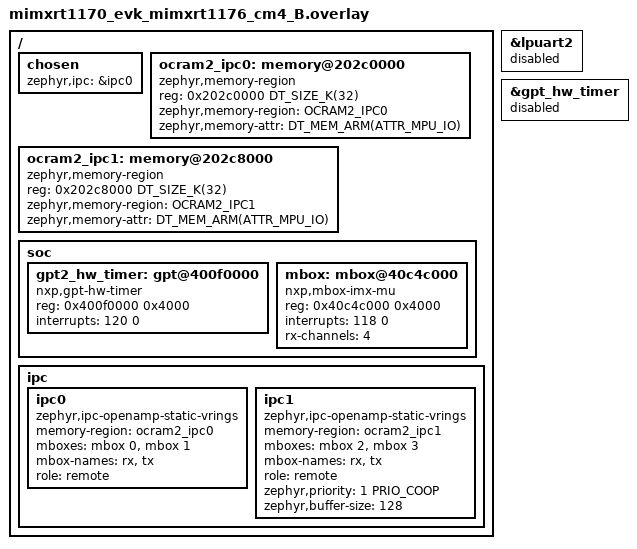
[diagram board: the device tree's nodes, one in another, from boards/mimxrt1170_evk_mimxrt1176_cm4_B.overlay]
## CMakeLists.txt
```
cmake_minimum_required(VERSION 3.20.0)
find_package(Zephyr REQUIRED HINTS $ENV{ZEPHYR_BASE})
project(cm4_rpmsg)

target_sources(app PRIVATE
    src/main.c
    src/ipc_handler.c
    src/cmd_dispatch.c
    src/debug.c
)
```

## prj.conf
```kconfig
CONFIG_IPC_SERVICE=y
CONFIG_MBOX=y
CONFIG_OPENAMP=y
CONFIG_OPENAMP_MASTER=n
CONFIG_HEAP_MEM_POOL_SIZE=4096
CONFIG_LOG=y
CONFIG_IPC_SERVICE_LOG_LEVEL_INF=y
CONFIG_MAIN_STACK_SIZE=2048
CONFIG_UART_CONSOLE=n
CONFIG_STDOUT_CONSOLE=n
CONFIG_BUILD_OUTPUT_INFO_HEADER=y
CONFIG_BUILD_OUTPUT_HEX=y
```

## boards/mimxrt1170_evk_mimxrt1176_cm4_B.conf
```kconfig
CONFIG_MBOX_NXP_IMX_MU=y
CONFIG_BUILD_OUTPUT_HEX=y
CONFIG_BUILD_OUTPUT_INFO_HEADER=y
CONFIG_SECOND_CORE_MCUX=y
```

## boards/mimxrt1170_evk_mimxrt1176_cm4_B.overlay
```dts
#include <zephyr/dt-bindings/ipc_service/static_vrings.h>
#include <zephyr/dt-bindings/memory-attr/memory-attr-arm.h>

/ {
    chosen {
        /delete-property/ zephyr,console;
        /delete-property/ zephyr,shell-uart;
        /delete-property/ zephyr,ipc;
        /delete-property/ zephyr,ipc_shm;
        zephyr,ipc = &ipc0;
    };

    ocram2_ipc0: memory@202c0000 {
        compatible = "zephyr,memory-region", "mmio-sram";
        reg = <0x202c0000 DT_SIZE_K(32)>;
        zephyr,memory-region = "OCRAM2_IPC0";
        zephyr,memory-attr = <DT_MEM_ARM(ATTR_MPU_IO)>;
    };

    ocram2_ipc1: memory@202c8000 {
        compatible = "zephyr,memory-region", "mmio-sram";
        reg = <0x202c8000 DT_SIZE_K(32)>;
        zephyr,memory-region = "OCRAM2_IPC1";
        zephyr,memory-attr = <DT_MEM_ARM(ATTR_MPU_IO)>;
    };

    soc {
        /delete-node/ gpt@400f0000;

        gpt2_hw_timer: gpt@400f0000 {
            compatible = "nxp,gpt-hw-timer";
            reg = <0x400f0000 0x4000>;
            interrupts = <120 0>;
            status = "okay";
        };

        /delete-node/ mailbox@40c4c000;

        mbox: mbox@40c4c000 {
            compatible = "nxp,mbox-imx-mu";
            reg = <0x40c4c000 0x4000>;
            interrupts = <118 0>;
            rx-channels = <4>;
            #mbox-cells = <1>;
            status = "okay";
        };
    };

    ipc {
        /delete-node/ ipc0;

        ipc0: ipc0 {
            compatible = "zephyr,ipc-openamp-static-vrings";
            memory-region = <&ocram2_ipc0>;
            mboxes = <&mbox 0>, <&mbox 1>;
            mbox-names = "rx", "tx";
            role = "remote";
            status = "okay";
        };

        ipc1: ipc1 {
            compatible = "zephyr,ipc-openamp-static-vrings";
            memory-region = <&ocram2_ipc1>;
            mboxes = <&mbox 2>, <&mbox 3>;
            mbox-names = "rx", "tx";
            role = "remote";
            zephyr,priority = <1 PRIO_COOP>;
            zephyr,buffer-size = <128>;
            status = "okay";
        };
    };
};

&lpuart2 {
    status = "disabled";
};

&gpt_hw_timer {
    status = "disabled";
};
```

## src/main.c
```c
#include <zephyr/kernel.h>
#include "ipc_handler.h"
#include "debug.h"

int main(void)
{
    int ret = ipc_handler_init();
    if (ret < 0) {
        printk("IPC init failed: %d\n", ret);
        return ret;
    }

    /* IPC is up - CM4 logs now route to CM7 console */
    CM4_LOG(DBG_MOD_MAIN, 1, "CM4 started, IPC ready");

    int count = 0;
    while (1) {
        CM4_LOG(DBG_MOD_MAIN, 2, "CM4 tick: %d", count++);
        k_sleep(K_SECONDS(5));
    }
    return 0;
}
```

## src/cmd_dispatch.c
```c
#include <zephyr/kernel.h>
#include <string.h>
#include <stdio.h>
#include "cmd_dispatch.h"
#include "ipc_handler.h"

#define CM4_FW_VERSION  "0.1.0"
#define CM4_BOARD_NAME  "MIMXRT1170-EVK Rev B"

static void cmd_ping(const char *args)
{
    ipc_send_resp("pong");
}

static void cmd_status(const char *args)
{
    char buf[IPC_MAX_PAYLOAD];
    snprintf(buf, sizeof(buf), "CM4 uptime: %u ms", k_uptime_get_32());
    ipc_send_resp(buf);
}

static void cmd_ver(const char *args)
{
    char buf[IPC_MAX_PAYLOAD];
    snprintf(buf, sizeof(buf),
             "Board:   %s\nFW Ver:  %s\nBuilt:   %s %s\nCM4 uptime: %u ms",
             CM4_BOARD_NAME, CM4_FW_VERSION, __DATE__, __TIME__,
             k_uptime_get_32());
    ipc_send_resp(buf);
}

static void cmd_log(const char *args)
{
    if (args && *args) {
        ipc_send_log(args);
        ipc_send_resp("log sent");
    } else {
        ipc_send_resp("Usage: log <message>");
    }
}

static void cmd_echo(const char *args)
{
    char buf[IPC_MAX_PAYLOAD];
    snprintf(buf, sizeof(buf), "echo: %s", args ? args : "");
    ipc_send_resp(buf);
}

static void cmd_shendpts(const char *args)
{
    char buf[IPC_MAX_PAYLOAD];
    snprintf(buf, sizeof(buf),
             "CM4 IPC ep:  cm4_ep\n"
             "OCRAM2_IPC0: 0x202C0000 (32KB) role=remote\n"
             "OCRAM2_IPC1: 0x202C8000 (32KB) role=remote");
    ipc_send_resp(buf);
}

typedef struct {
    const char *name;
    void (*handler)(const char *args);
} cmd_entry_t;

static const cmd_entry_t cmd_table[] = {
    { "ping",     cmd_ping     },
    { "status",   cmd_status   },
    { "ver",      cmd_ver      },
    { "log",      cmd_log      },
    { "echo",     cmd_echo     },
    { "shendpts", cmd_shendpts },
    /* Add new commands here */
};

void cmd_dispatch(const char *cmd)
{
    char name[32] = {0};
    const char *args = "";

    const char *space = strchr(cmd, ' ');
    if (space) {
        size_t nlen = (size_t)(space - cmd);
        if (nlen >= sizeof(name)) nlen = sizeof(name) - 1;
        memcpy(name, cmd, nlen);
        args = space + 1;
    } else {
        strncpy(name, cmd, sizeof(name) - 1);
    }

    for (size_t i = 0; i < ARRAY_SIZE(cmd_table); i++) {
        if (strcmp(name, cmd_table[i].name) == 0) {
            cmd_table[i].handler(args);
            return;
        }
    }

    char resp[IPC_MAX_PAYLOAD];
    snprintf(resp, sizeof(resp), "Unknown command: %s", name);
    ipc_send_resp(resp);
}
```

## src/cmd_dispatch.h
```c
#ifndef CMD_DISPATCH_H
#define CMD_DISPATCH_H

void cmd_dispatch(const char *cmd);

#endif
```

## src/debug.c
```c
#include <zephyr/kernel.h>
#include <stdio.h>
#include <stdarg.h>
#include <string.h>
#include "debug.h"
#include "ipc_handler.h"

/* Default: all modules enabled, level 1 */
uint32_t     DebugMask  = 0xFFFFFFFF;
uint32_t     DebugLevel = 1;

debug_bits_t DebugBits[DBG_MOD_COUNT] = {
    [DBG_MOD_MAIN] = { .dbgBit = (1u << DBG_MOD_MAIN), .name = "MAIN" },
    [DBG_MOD_IPC]  = { .dbgBit = (1u << DBG_MOD_IPC),  .name = "IPC"  },
    [DBG_MOD_APP]  = { .dbgBit = (1u << DBG_MOD_APP),  .name = "APP"  },
};

void ipc_log_send(const char *fmt, ...)
{
    char buf[220];
    va_list args;

    va_start(args, fmt);
    vsnprintf(buf, sizeof(buf), fmt, args);
    va_end(args);

    /* Try IPC first; fall back to printk if IPC not ready */
    if (ipc_send_log(buf) < 0) {
        printk("%s\n", buf);
    }
}
```

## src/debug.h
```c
#ifndef DEBUG_H
#define DEBUG_H

#include <stdint.h>

/* Module indices - add new modules here */
#define DBG_MOD_MAIN     0
#define DBG_MOD_IPC      1
#define DBG_MOD_APP      2
/* Add more as needed, max 32 */
#define DBG_MOD_COUNT    3

typedef struct {
    uint32_t    dbgBit;
    const char *name;
} debug_bits_t;

extern uint32_t        DebugMask;
extern uint32_t        DebugLevel;
extern debug_bits_t    DebugBits[DBG_MOD_COUNT];

/* Logging macros - output goes via IPC to CM7 once IPC is ready,
 * falls back to printk before IPC is up */
#define DBG_MSK_LVL_BEGIN(m, l) \
    if ((DebugLevel >= (uint32_t)(l)) && (DebugMask & DebugBits[m].dbgBit)) {
#define DBG_END }

void ipc_log_send(const char *fmt, ...);

/* Convenience wrapper keeping the [CM4][ts] prefix */
#define CM4_LOG(m, l, fmt, ...) \
    DBG_MSK_LVL_BEGIN(m, l) \
        ipc_log_send("[CM4][%u] " fmt, k_uptime_get_32(), ##__VA_ARGS__); \
    DBG_END

#endif /* DEBUG_H */
```

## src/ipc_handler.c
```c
#include <zephyr/kernel.h>
#include <zephyr/ipc/ipc_service.h>
#include <string.h>
#include "ipc_handler.h"
#include "cmd_dispatch.h"

static struct ipc_ept ep;
static K_SEM_DEFINE(bound_sem, 0, 1);
static bool bound_once = false;
static bool ipc_ready  = false;

static void ep_bound(void *priv)
{
    if (!bound_once) {
        bound_once = true;
        ipc_ready  = true;
        k_sem_give(&bound_sem);
    }
}

static void ep_recv(const void *data, size_t len, void *priv)
{
    if (len < sizeof(ipc_message_t)) {
        return;
    }

    const ipc_message_t *msg = (const ipc_message_t *)data;

    switch (msg->msg_type) {
    case IPC_MSG_TYPE_CMD:
        cmd_dispatch(msg->payload);
        break;
    default:
        break;
    }
}

static struct ipc_ept_cfg ep_cfg = {
    .name = "cm4_ep",
    .cb = {
        .bound    = ep_bound,
        .received = ep_recv,
    },
};

int ipc_handler_init(void)
{
    const struct device *ipc_dev = DEVICE_DT_GET(DT_CHOSEN(zephyr_ipc));
    int ret;

    ret = ipc_service_open_instance(ipc_dev);
    if (ret < 0 && ret != -EALREADY) {
        return ret;
    }

    ret = ipc_service_register_endpoint(ipc_dev, &ep, &ep_cfg);
    if (ret < 0) {
        return ret;
    }

    k_sem_take(&bound_sem, K_FOREVER);
    return 0;
}

int ipc_send_log(const char *msg)
{
    if (!ipc_ready) {
        return -EAGAIN;
    }

    ipc_message_t out = {0};
    out.msg_type     = IPC_MSG_TYPE_LOG;
    out.timestamp_ms = k_uptime_get_32();

    strncpy(out.payload, msg, sizeof(out.payload) - 1);

    return ipc_service_send(&ep, &out, sizeof(out));
}

int ipc_send_resp(const char *resp)
{
    if (!ipc_ready) {
        return -EAGAIN;
    }

    ipc_message_t out = {0};
    out.msg_type     = IPC_MSG_TYPE_RESP;
    out.timestamp_ms = k_uptime_get_32();

    strncpy(out.payload, resp, sizeof(out.payload) - 1);

    return ipc_service_send(&ep, &out, sizeof(out));
}
```

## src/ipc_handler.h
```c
#ifndef IPC_HANDLER_H
#define IPC_HANDLER_H

#include <stdint.h>
#include <stddef.h>

/* Must match cm7_shell/src/ipc_handler.h */
#define IPC_MSG_TYPE_LOG     0x01
#define IPC_MSG_TYPE_CMD     0x02
#define IPC_MSG_TYPE_RESP    0x03

#define IPC_MAX_PAYLOAD      220

typedef struct {
    uint8_t  msg_type;
    uint8_t  reserved[3];
    uint32_t timestamp_ms;
    char     payload[IPC_MAX_PAYLOAD];
} ipc_message_t;

/* CM4-side API */
int  ipc_handler_init(void);
int  ipc_send_log(const char *msg);
int  ipc_send_resp(const char *resp);

#endif /* IPC_HANDLER_H */
```
